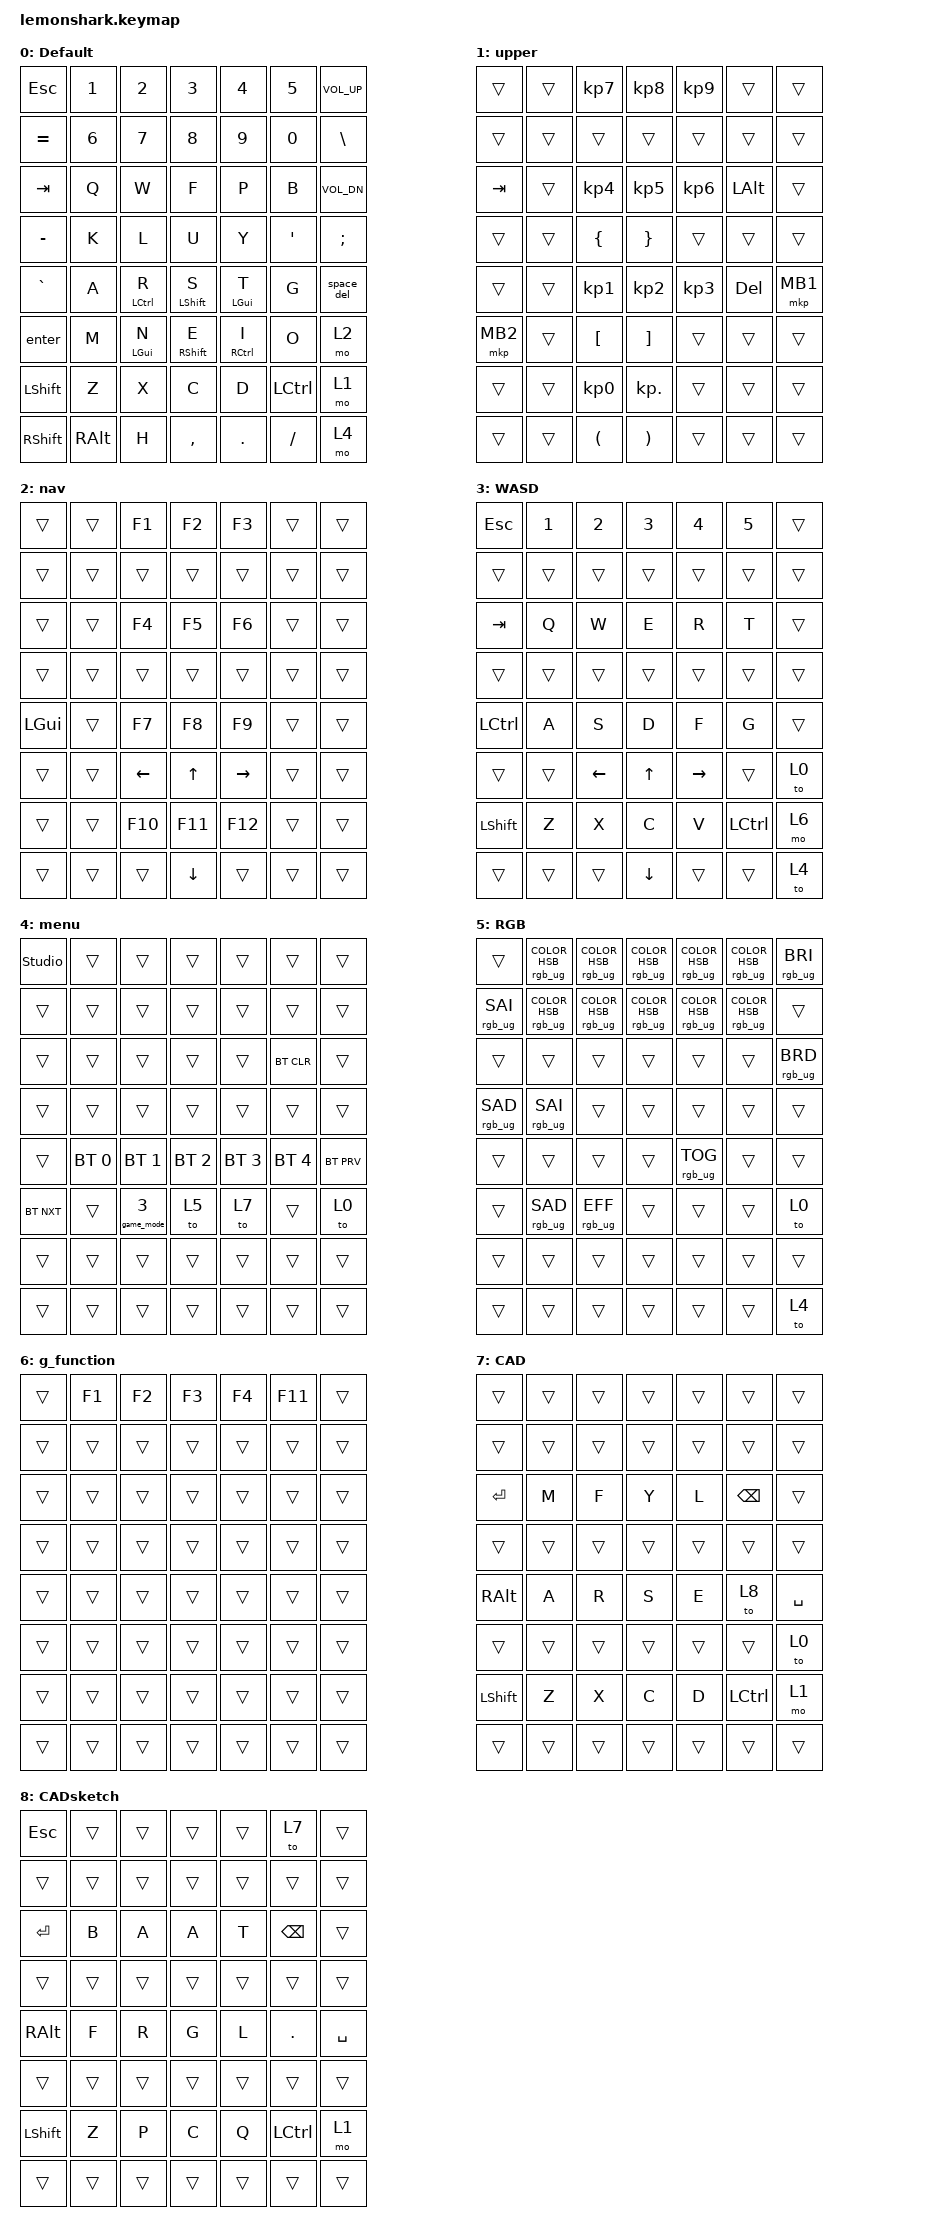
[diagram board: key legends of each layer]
#include <behaviors.dtsi>
#include <dt-bindings/zmk/bt.h>
#include <dt-bindings/zmk/keys.h>
#include <dt-bindings/zmk/pointing.h>
#include <dt-bindings/zmk/rgb.h>

/ {
    combos {
        compatible = "zmk,combos";

        combo_v {
            bindings = <&kp V>;
            key-positions = <45 46>;
            layers = <0>;
        };

        combo_j {
            bindings = <&kp J>;
            key-positions = <18 17>;
            layers = <0>;
        };

        middle {
            bindings = <&mkp MB3>;
            key-positions = <34 35>;
            layers = <1>;
        };
    };

    behaviors {
        enter: enter {
            compatible = "zmk,behavior-mod-morph";
            label = "ENTER";
            bindings = <&kp BSPC>, <&kp RET>;

            #binding-cells = <0>;
            mods = <(MOD_RALT)>;
        };

        space_del: space_del {
            compatible = "zmk,behavior-mod-morph";
            label = "SPACE_DEL";
            bindings = <&kp SPACE>, <&kp DELETE>;

            #binding-cells = <0>;
            mods = <(MOD_LSFT)>;
        };

        game_mode: game_mode {
            compatible = "zmk,behavior-toggle-layer";
            label = "GAME_MODE";
            #binding-cells = <1>;
            toggle-mode = "flip";
        };

        hrm_index: hrm_index {
            compatible = "zmk,behavior-hold-tap";
            label = "HRM_INDEX";
            bindings = <&kp>, <&kp>;

            #binding-cells = <2>;
            hold-trigger-key-positions = <32>;
            tapping-term-ms = <250>;
            flavor = "tap-preferred";
        };
    };

    macros {
        o_umlaut: o_umlaut {
            compatible = "zmk,behavior-macro";
            #binding-cells = <0>;
            bindings = <&kp RA(O) &kt RIGHT_ALT &kp KP_NUMBER_0 &kp KP_NUMBER_2 &kp KP_NUMBER_4 &kp KP_NUMBER_6 &kt RALT>;
            label = "O_UMLAUT";
        };

        u_umlaut: u_umlaut {
            compatible = "zmk,behavior-macro";
            #binding-cells = <0>;
            bindings = <&kp RA(O) &kt RIGHT_ALT &kp KP_NUMBER_0 &kp KP_NUMBER_2 &kp KP_NUMBER_5 &kp KP_NUMBER_2 &kt RALT>;
            label = "U_UMLAUT";
        };

        e_umlaut: e_umlaut {
            compatible = "zmk,behavior-macro";
            #binding-cells = <0>;
            bindings = <&kp RA(O) &kt RIGHT_ALT &kp KP_NUMBER_0 &kp KP_NUMBER_2 &kp KP_NUMBER_3 &kp KP_NUMBER_5 &kt RALT>;
            label = "E_UMLAUT";
        };

        a_umlaut: a_umlaut {
            compatible = "zmk,behavior-macro";
            #binding-cells = <0>;
            bindings = <&kp RA(O) &kt RIGHT_ALT &kp KP_NUMBER_0 &kp KP_NUMBER_2 &kp KP_NUMBER_2 &kp KP_NUMBER_8 &kt RALT>;
            label = "A_UMLAUT";
        };

        eszett: eszett {
            compatible = "zmk,behavior-macro";
            #binding-cells = <0>;
            bindings = <&kp RA(O) &kt RIGHT_ALT &kp KP_NUMBER_0 &kp KP_NUMBER_2 &kp KP_NUMBER_2 &kp KP_NUMBER_3 &kt RALT>;
            label = "ESZETT";
        };

        alt_tab: alt_tab {
            compatible = "zmk,behavior-macro";
            #binding-cells = <0>;
            bindings = <&alt_tab &kp RIGHT_ALT &kp TAB>;
            label = "ALT_TAB";
        };
    };

    keymap {
        compatible = "zmk,keymap";

        colemak-dh {
            bindings = <
&kp ESC    &kp N1  &kp N2              &kp N3               &kp N4             &kp N5     &kp C_VOL_UP
                                                                                                        &kp EQUAL  &kp N6    &kp N7             &kp N8              &kp N9              &kp N0    &kp BSLH
&kp TAB    &kp Q   &kp W               &kp F                &kp P              &kp B      &kp C_VOL_DN
                                                                                                        &kp MINUS  &kp K     &kp L              &kp U               &kp Y               &kp SQT   &kp SEMI
&kp GRAVE  &kp A   &hrm_index LCTRL R  &hrm_index LSHIFT S  &hrm_index LGUI T  &kp G      &space_del
                                                                                                        &enter     &kp M     &hrm_index LGUI N  &hrm_index RSHFT E  &hrm_index RCTRL I  &kp O     &mo 2
&kp LSHFT  &kp Z   &kp X               &kp C                &kp D              &kp LCTRL  &mo 1
                                                                                                        &kp RSHFT  &kp RALT  &kp H              &kp COMMA           &kp DOT             &kp FSLH  &mo 4
            >;

            label = "Default";
        };

        brackets {
            bindings = <
&trans   &trans  &kp KP_NUMBER_7  &kp KP_NUMBER_8  &kp KP_NUMBER_9  &trans        &trans
                                                                                            &trans    &trans  &trans                &trans                 &trans  &trans  &trans
&kp TAB  &trans  &kp KP_NUMBER_4  &kp KP_NUMBER_5  &kp KP_NUMBER_6  &kp LEFT_ALT  &trans
                                                                                            &trans    &trans  &kp LBRC              &kp RBRC               &trans  &trans  &trans
&trans   &trans  &kp KP_NUMBER_1  &kp KP_NUMBER_2  &kp KP_NUMBER_3  &kp DELETE    &mkp MB1
                                                                                            &mkp MB2  &trans  &kp LEFT_BRACKET      &kp RBKT               &trans  &trans  &trans
&trans   &trans  &kp KP_NUMBER_0  &kp KP_DOT       &trans           &trans        &trans
                                                                                            &trans    &trans  &kp LEFT_PARENTHESIS  &kp RIGHT_PARENTHESIS  &trans  &trans  &trans
            >;

            label = "upper";
        };

        nav {
            bindings = <
&trans    &trans  &kp F1   &kp F2   &kp F3   &trans  &trans
                                                             &trans  &trans  &trans    &trans    &trans     &trans  &trans
&trans    &trans  &kp F4   &kp F5   &kp F6   &trans  &trans
                                                             &trans  &trans  &trans    &trans    &trans     &trans  &trans
&kp LGUI  &trans  &kp F7   &kp F8   &kp F9   &trans  &trans
                                                             &trans  &trans  &kp LEFT  &kp UP    &kp RIGHT  &trans  &trans
&trans    &trans  &kp F10  &kp F11  &kp F12  &trans  &trans
                                                             &trans  &trans  &trans    &kp DOWN  &trans     &trans  &trans
            >;

            label = "nav";
        };

        games {
            bindings = <
&kp ESC     &kp N1  &kp N2  &kp N3  &kp N4  &kp N5     &trans
                                                               &trans  &trans  &trans    &trans    &trans     &trans  &trans
&kp TAB     &kp Q   &kp W   &kp E   &kp R   &kp T      &trans
                                                               &trans  &trans  &trans    &trans    &trans     &trans  &trans
&kp LCTRL   &kp A   &kp S   &kp D   &kp F   &kp G      &trans
                                                               &trans  &trans  &kp LEFT  &kp UP    &kp RIGHT  &trans  &to 0
&kp LSHIFT  &kp Z   &kp X   &kp C   &kp V   &kp LCTRL  &mo 6
                                                               &trans  &trans  &trans    &kp DOWN  &trans     &trans  &to 4
            >;

            label = "WASD";
        };

        menu {
            bindings = <
&studio_unlock  &trans        &trans        &trans        &trans        &trans        &trans
                                                                                                  &trans      &trans  &trans        &trans  &trans  &trans  &trans
&trans          &trans        &trans        &trans        &trans        &bt BT_CLR    &trans
                                                                                                  &trans      &trans  &trans        &trans  &trans  &trans  &trans
&trans          &bt BT_SEL 0  &bt BT_SEL 1  &bt BT_SEL 2  &bt BT_SEL 3  &bt BT_SEL 4  &bt BT_PRV
                                                                                                  &bt BT_NXT  &trans  &game_mode 3  &to 5   &to 7   &trans  &to 0
&trans          &trans        &trans        &trans        &trans        &trans        &trans
                                                                                                  &trans      &trans  &trans        &trans  &trans  &trans  &trans
            >;

            label = "menu";
        };

        lighting {
            bindings = <
&trans  &rgb_ug RGB_COLOR_HSB(0,0,100)  &rgb_ug RGB_COLOR_HSB(286,91,50)  &rgb_ug RGB_COLOR_HSB(137,66,43)  &rgb_ug RGB_COLOR_HSB(175,91,50)  &rgb_ug RGB_COLOR_HSB(54,95,51)  &rgb_ug RGB_BRI
                                                                                                                                                                                                &rgb_ug RGB_SAI  &rgb_ug RGB_COLOR_HSB(0,97,51)  &rgb_ug RGB_COLOR_HSB(263,100,52)  &rgb_ug RGB_COLOR_HSB(20,99,50)  &rgb_ug RGB_COLOR_HSB(225,94,50)  &rgb_ug RGB_COLOR_HSB(0,16,91)  &trans
&trans  &trans                          &trans                            &trans                            &trans                            &trans                           &rgb_ug RGB_BRD
                                                                                                                                                                                                &rgb_ug RGB_SAD  &rgb_ug RGB_SAI                 &trans                             &trans                           &trans                            &trans                          &trans
&trans  &trans                          &trans                            &trans                            &rgb_ug RGB_TOG                   &trans                           &trans
                                                                                                                                                                                                &trans           &rgb_ug RGB_SAD                 &rgb_ug RGB_EFF                    &trans                           &trans                            &trans                          &to 0
&trans  &trans                          &trans                            &trans                            &trans                            &trans                           &trans
                                                                                                                                                                                                &trans           &trans                          &trans                             &trans                           &trans                            &trans                          &to 4
            >;

            label = "RGB";
        };

        game_f {
            bindings = <
&trans  &kp F1  &kp F2  &kp F3  &kp F4  &kp F11  &trans
                                                         &trans  &trans  &trans  &trans  &trans  &trans  &trans
&trans  &trans  &trans  &trans  &trans  &trans   &trans
                                                         &trans  &trans  &trans  &trans  &trans  &trans  &trans
&trans  &trans  &trans  &trans  &trans  &trans   &trans
                                                         &trans  &trans  &trans  &trans  &trans  &trans  &trans
&trans  &trans  &trans  &trans  &trans  &trans   &trans
                                                         &trans  &trans  &trans  &trans  &trans  &trans  &trans
            >;

            label = "g_function";
        };

        onshape {
            bindings = <
&trans     &trans  &trans  &trans  &trans  &trans     &trans
                                                                 &trans  &trans  &trans  &trans  &trans  &trans  &trans
&kp RET    &kp M   &kp F   &kp Y   &kp L   &kp BSPC   &trans
                                                                 &trans  &trans  &trans  &trans  &trans  &trans  &trans
&kp RALT   &kp A   &kp R   &kp S   &kp E   &to 8      &kp SPACE
                                                                 &trans  &trans  &trans  &trans  &trans  &trans  &to 0
&kp LSHFT  &kp Z   &kp X   &kp C   &kp D   &kp LCTRL  &mo 1
                                                                 &trans  &trans  &trans  &trans  &trans  &trans  &trans
            >;

            label = "CAD";
        };

        onshape_sketch {
            bindings = <
&kp ESC    &trans  &trans  &trans  &trans  &to 7      &trans
                                                                 &trans  &trans  &trans  &trans  &trans  &trans  &trans
&kp RET    &kp B   &kp A   &kp A   &kp T   &kp BSPC   &trans
                                                                 &trans  &trans  &trans  &trans  &trans  &trans  &trans
&kp RALT   &kp F   &kp R   &kp G   &kp L   &kp DOT    &kp SPACE
                                                                 &trans  &trans  &trans  &trans  &trans  &trans  &trans
&kp LSHFT  &kp Z   &kp P   &kp C   &kp Q   &kp LCTRL  &mo 1
                                                                 &trans  &trans  &trans  &trans  &trans  &trans  &trans
            >;

            label = "CADsketch";
        };
    };

    conditional_layers { compatible = "zmk,conditional-layers"; };
};
